# STM32H745_CM4 register map
File version: 2.0
CPU: CM4 r0p1, little endian, MPU, FPU, 4 interrupt priority bits
Registers are 32-bit, read-write, reset 0x0 unless marked. A register's access mark holds for its fields unless they carry their own. Offsets are from the block's base; [hi:lo] are bit positions; {n}, {i} and the like mark numbered series.

## DMAMUX2 — DMAMUX
Base 0x58025800
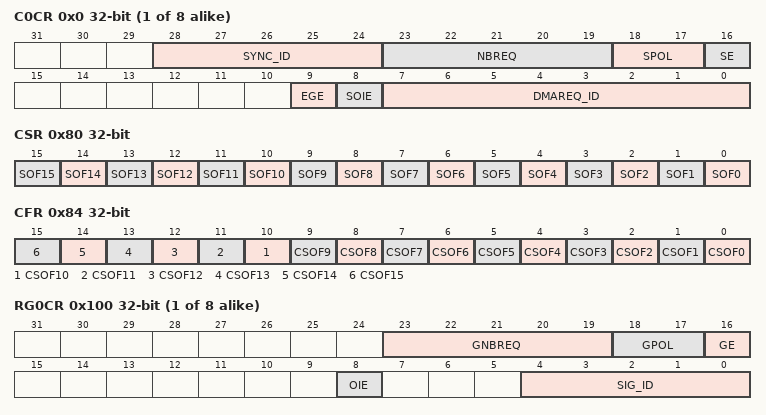
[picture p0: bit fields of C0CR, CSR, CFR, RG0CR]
{0x0+4i} C{i}CR (i=0..7) — DMAMux - DMA request line multiplexer channel x control register
  [28:24] SYNC_ID — Synchronization input selected
    {v}=dmamux2_evt{v} (Signal `dmamux2_evt{v}` selected as synchronization input) (v=0..5); 6=lpuart1_rx_wkup (Signal `lpuart1_rx_wkup` selected as synchronization input); 7=lpuart1_tx_wkup (Signal `lpuart1_tx_wkup` selected as synchronization input); 8=lptim2_out (Signal `lptim2_out` selected as synchronization input); 9=lptim3_out (Signal `lptim3_out` selected as synchronization input); 10=i2c4_wkup (Signal `i2c4_wkup` selected as synchronization input); 11=spi6_wkup (Signal `spi6_wkup` selected as synchronization input); 12=comp1_out (Signal `comp1_out` selected as synchronization input); 13=rtc_wkup (Signal `rtc_wkup` selected as synchronization input); 14=syscfg_exti0_mux (Signal `syscfg_exti0_mux` selected as synchronization input); 15=syscfg_exti2_mux (Signal `syscfg_exti2_mux` selected as synchronization input)
  [23:19] NBREQ — Number of DMA requests to forward Defines the number of DMA requests forwarded before output event is generated. In synchronous mode, it also defines the number of DMA requests to forward after a synchronization event, then stop forwarding. The actual number of DMA requests forwarded is NBREQ+1. Note: This field can only be written when both SE and EGE bits are reset.
  [18:17] SPOL — Synchronization event type selector Defines the synchronization event on the selected synchronization input:
    0=NoEdge (No event, i.e. no synchronization nor detection); 1=RisingEdge; 2=FallingEdge; 3=BothEdges (Rising and falling edges)
  [16] SE — Synchronous operating mode enable/disable
    0=Disabled (Synchronization disabled); 1=Enabled (Synchronization enabled)
  [9] EGE — Event generation enable/disable
    0=Disabled (Event generation disabled); 1=Enabled (Event generation enabled)
  [8] SOIE — Interrupt enable at synchronization event overrun
    0=Disabled (Synchronization overrun interrupt disabled); 1=Enabled (Synchronization overrun interrupt enabled)
  [7:0] DMAREQ_ID — Input DMA request line selected
    0=none (No signal selected as request input); {v}=dmamux2_req_gen{v-1} (Signal `dmamux2_req_gen{v-1}` selected as request input) (v=1..8); 9=lpuart1_rx_dma (Signal `lpuart1_rx_dma` selected as request input); 10=lpuart1_tx_dma (Signal `lpuart1_tx_dma` selected as request input); 11=spi6_rx_dma (Signal `spi6_rx_dma` selected as request input); 12=spi6_tx_dma (Signal `spi6_tx_dma` selected as request input); 13=i2c4_rx_dma (Signal `i2c4_rx_dma` selected as request input); 14=i2c4_tx_dma (Signal `i2c4_tx_dma` selected as request input); 15=sai4_a_dma (Signal `sai4_a_dma` selected as request input); 16=sai4_b_dma (Signal `sai4_b_dma` selected as request input); 17=adc3_dma (Signal `adc3_dma` selected as request input)
0x80 CSR ro — DMAMUX request line multiplexer interrupt channel status register
  [n] SOF{n} (n=0..15) — Synchronization overrun event flag
    0=NoSyncEvent (No synchronization event occured on a DMA request line multiplexer channel x, while the DMA request counter value is lower than NBREQ); 1=SyncEvent (Synchronization event occured on a DMA request line multiplexer channel x, while the DMA request counter value is lower than NBREQ)
0x84 CFR wo — DMAMUX request line multiplexer interrupt clear flag register
  [n] CSOF{n} (n=0..15) write-1-clears — Clear synchronization overrun event flag
    1=Clear synchronization flag
{0x100+4i} RG{i}CR (i=0..7) — DMAMux - DMA request generator channel x control register
  [23:19] GNBREQ — Number of DMA requests to generate Defines the number of DMA requests generated after a trigger event, then stop generating. The actual number of generated DMA requests is GNBREQ+1. Note: This field can only be written when GE bit is reset.
  [18:17] GPOL — DMA request generator trigger event type selection Defines the trigger event on the selected DMA request trigger input
    0=NoEdge (No event, i.e. no detection nor generation); 1=RisingEdge; 2=FallingEdge; 3=BothEdges (Rising and falling edges)
  [16] GE — DMA request generator channel enable/disable
    0=Disabled (DMA request generation disabled); 1=Enabled (DMA request enabled)
  [8] OIE — Interrupt enable at trigger event overrun
    0=Disabled (Trigger overrun interrupt disabled); 1=Enabled (Trigger overrun interrupt enabled)
  [4:0] SIG_ID — DMA request trigger input selected
    {v}=dmamux2_evt{v} (Signal `dmamux2_evt{v}` selected as trigger input) (v=0..6); 7=lpuart_rx_wkup (Signal `lpuart_rx_wkup` selected as trigger input); 8=lpuart_tx_wkup (Signal `lpuart_tx_wkup` selected as trigger input); 9=lptim2_wkup (Signal `lptim2_wkup` selected as trigger input); 10=lptim2_out (Signal `lptim2_out` selected as trigger input); 11=lptim3_wkup (Signal `lptim3_wkup` selected as trigger input); 12=lptim3_out (Signal `lptim3_out` selected as trigger input); 13=lptim4_ait (Signal `lptim4_ait` selected as trigger input); 14=lptim5_ait (Signal `lptim5_ait` selected as trigger input); 15=i2c4_wkup (Signal `i2c4_wkup` selected as trigger input); 16=spi6_wkup (Signal `spi6_wkup` selected as trigger input); 17=comp1_out (Signal `comp1_out` selected as trigger input); 18=comp2_out (Signal `comp2_out` selected as trigger input); 19=rtc_wkup (Signal `rtc_wkup` selected as trigger input); 20=syscfg_exti0_mux (Signal `syscfg_exti0_mux` selected as trigger input); 21=syscfg_exti2_mux (Signal `syscfg_exti2_mux` selected as trigger input); 22=i2c4_event_it (Signal `i2c4_event_it` selected as trigger input); 23=spi6_it (Signal `spi6_it` selected as trigger input); 24=lpuart1_it_t (Signal `lpuart1_it_t` selected as trigger input); 25=lpuart1_it_r (Signal `lpuart1_it_r` selected as trigger input); 26=adc3_it (Signal `adc3_it` selected as trigger input); 27=adc3_awd1 (Signal `adc3_awd1` selected as trigger input); 28=bdma_ch0_it (Signal `bdma_ch0_it` selected as trigger input); 29=bdma_ch1_it (Signal `bdma_ch1_it` selected as trigger input)
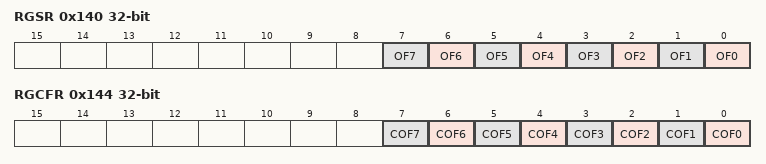
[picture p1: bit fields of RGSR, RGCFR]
0x140 RGSR ro — DMAMux - DMA request generator status register
  [n] OF{n} (n=0..7) — Trigger event overrun flag The flag is set when a trigger event occurs on DMA request generator channel x, while the DMA request generator counter value is lower than GNBREQ. The flag is cleared by writing 1 to the corresponding COFx bit in DMAMUX_RGCFR register.
    0=NoTrigger (No new trigger event occured on DMA request generator channel x, before the request counter underrun); 1=Trigger (New trigger event occured on DMA request generator channel x, before the request counter underrun)
0x144 RGCFR wo — DMAMux - DMA request generator clear flag register
  [n] COF{n} (n=0..7) write-1-clears — Clear trigger event overrun flag Upon setting, this bit clears the corresponding overrun flag OFx in the DMAMUX_RGCSR register.
    1=Clear overrun flag
